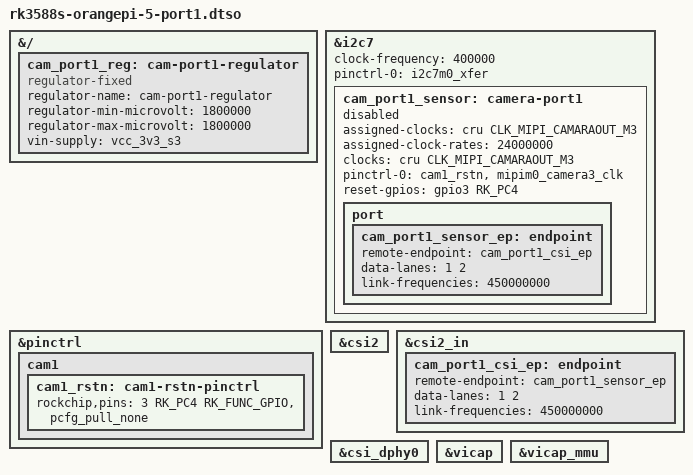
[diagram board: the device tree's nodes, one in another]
// SPDX-License-Identifier: (GPL-2.0+ OR MIT)
/*
 * Orange Pi 5 / 5B CAM1 (port1): Inno CSI D-PHY + CSI2 on i2c7.
 *
 * Enables the connector and publishes the labels a sensor overlay binds to:
 *   cam_port1_sensor, cam_port1_sensor_ep, cam_port1_csi_ep, cam_port1_reg
 * The sensor node stays disabled until a sensor overlay enables it.
 */

/dts-v1/;
/plugin/;

#include <dt-bindings/clock/rockchip,rk3588-cru.h>
#include <dt-bindings/gpio/gpio.h>
#include <dt-bindings/pinctrl/rockchip.h>

&{/} {
	cam_port1_reg: cam-port1-regulator {
		compatible = "regulator-fixed";
		regulator-name = "cam-port1-regulator";
		regulator-min-microvolt = <1800000>;
		regulator-max-microvolt = <1800000>;
		vin-supply = <&vcc_3v3_s3>;
	};
};

&i2c7 {
	#address-cells = <1>;
	#size-cells = <0>;
	clock-frequency = <400000>;
	pinctrl-names = "default";
	pinctrl-0 = <&i2c7m0_xfer>;
	status = "okay";

	cam_port1_sensor: camera-port1 {
		status = "disabled";
		assigned-clocks = <&cru CLK_MIPI_CAMARAOUT_M3>;
		assigned-clock-rates = <24000000>;
		clocks = <&cru CLK_MIPI_CAMARAOUT_M3>;
		pinctrl-names = "default";
		pinctrl-0 = <&cam1_rstn &mipim0_camera3_clk>;
		reset-gpios = <&gpio3 RK_PC4 GPIO_ACTIVE_HIGH>;

		port {
			cam_port1_sensor_ep: endpoint {
				remote-endpoint = <&cam_port1_csi_ep>;
				data-lanes = <1 2>;
				link-frequencies = /bits/ 64 <450000000>;
			};
		};
	};
};

&pinctrl {
	cam1 {
		cam1_rstn: cam1-rstn-pinctrl {
			rockchip,pins = <3 RK_PC4 RK_FUNC_GPIO &pcfg_pull_none>;
		};
	};
};

&csi2 {
	status = "okay";
};

&csi2_in {
	cam_port1_csi_ep: endpoint {
		remote-endpoint = <&cam_port1_sensor_ep>;
		data-lanes = <1 2>;
		link-frequencies = /bits/ 64 <450000000>;
	};
};

&csi_dphy0 {
	status = "okay";
};

&vicap {
	status = "okay";
};

&vicap_mmu {
	status = "okay";
};
